AUTOSAR XML (schema 00044)
package /DiagAResourceConsumption/SwAddrMethods
  sw addr method CODE: memory-allocation-keyword-policy=ADDR-METHOD-SHORT-NAME, section-type=CODE
  sw addr method CONST: memory-allocation-keyword-policy=ADDR-METHOD-SHORT-NAME-AND-ALIGNMENT, section-type=CONST
package /ComponentTypes
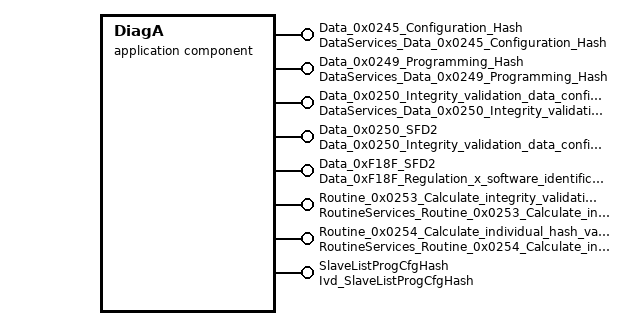
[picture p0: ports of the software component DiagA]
  application sw component type DiagA
    8 x provide port:
      Data_0x0245_Configuration_Hash: provided-interface=DataServices_Data_0x0245_Configuration_Hash
        provided-com-specs:
          operation=DataServices_Data_0x0245_Configuration_Hash/ConditionCheckRead, queue-length=1
          operation=DataServices_Data_0x0245_Configuration_Hash/ReadData, queue-length=1
      Data_0x0249_Programming_Hash: provided-interface=DataServices_Data_0x0249_Programming_Hash
        provided-com-specs:
          operation=DataServices_Data_0x0249_Programming_Hash/ConditionCheckRead, queue-length=1
          operation=DataServices_Data_0x0249_Programming_Hash/ReadData, queue-length=1
      Data_0x0250_Integrity_validation_data_configuration_list: provided-interface=DataServices_Data_0x0250_Integrity_validation_data_configuration_list
        provided-com-specs:
          operation=DataServices_Data_0x0250_Integrity_validation_data_configuration_list/ConditionCheckRead, queue-length=1
          operation=DataServices_Data_0x0250_Integrity_validation_data_configuration_list/ReadData, queue-length=1
          operation=DataServices_Data_0x0250_Integrity_validation_data_configuration_list/ReadDataLength, queue-length=1
          operation=DataServices_Data_0x0250_Integrity_validation_data_configuration_list/WriteData, queue-length=1
      Data_0x0250_SFD2: provided-interface=Data_0x0250_Integrity_validation_data_configuration_list_SFD2
        provided-com-specs:
          operation=Data_0x0250_Integrity_validation_data_configuration_list_SFD2/ConditionCheckRead, queue-length=1
          operation=Data_0x0250_Integrity_validation_data_configuration_list_SFD2/ReadData, queue-length=1
          operation=Data_0x0250_Integrity_validation_data_configuration_list_SFD2/ReadDataLength, queue-length=1
          operation=Data_0x0250_Integrity_validation_data_configuration_list_SFD2/WriteData, queue-length=1
      Data_0xF18F_SFD2: provided-interface=Data_0xF18F_Regulation_x_software_identification_numbers_SFD2
        provided-com-specs:
          operation=Data_0xF18F_Regulation_x_software_identification_numbers_SFD2/ConditionCheckRead, queue-length=1
          operation=Data_0xF18F_Regulation_x_software_identification_numbers_SFD2/ReadData, queue-length=1
          operation=Data_0xF18F_Regulation_x_software_identification_numbers_SFD2/ReadDataLength, queue-length=1
          operation=Data_0xF18F_Regulation_x_software_identification_numbers_SFD2/WriteData, queue-length=1
      Routine_0x0253_Calculate_integrity_validation_data_Start: server-com-spec{operation=RoutineServices_Routine_0x0253_Calculate_integrity_validation_data_Start/Start, queue-length=1}, provided-interface=RoutineServices_Routine_0x0253_Calculate_integrity_validation_data_Start
      Routine_0x0254_Calculate_individual_hash_value_Start: server-com-spec{operation=RoutineServices_Routine_0x0254_Calculate_individual_hash_value_Start/Start, queue-length=1}, provided-interface=RoutineServices_Routine_0x0254_Calculate_individual_hash_value_Start
      SlaveListProgCfgHash: provided-com-specs=[{operation=Data, queue-length=1}, {operation=Hash, queue-length=1}], provided-interface=Ivd_SlaveListProgCfgHash
    behavior DiagA_InternalBehavior
      20 x operation invoked event:
        OIT_Data_0x0245_Configuration_Hash_ConditionCheckRead_Data_0x0245_Configuration_Hash_ConditionCheckRead: start-on-event=Data_0x0245_Configuration_Hash_ConditionCheckRead, operation=Data_0x0245_Configuration_Hash.ConditionCheckRead
        OIT_Data_0x0245_Configuration_Hash_ReadData_Data_0x0245_Configuration_Hash_ReadData: start-on-event=Data_0x0245_Configuration_Hash_ReadData, operation=Data_0x0245_Configuration_Hash.ReadData
        OIT_Data_0x0249_Programming_Hash_ConditionCheckRead_Data_0x0249_Programming_Hash_ConditionCheckRead: start-on-event=Data_0x0249_Programming_Hash_ConditionCheckRead, operation=Data_0x0249_Programming_Hash.ConditionCheckRead
        OIT_Data_0x0249_Programming_Hash_ReadData_Data_0x0249_Programming_Hash_ReadData: start-on-event=Data_0x0249_Programming_Hash_ReadData, operation=Data_0x0249_Programming_Hash.ReadData
        OIT_Data_0x0250_Integrity_validation_data_configuration_list_ConditionCheckRead_Data_0x0250_Integrity_validation_data_coF4607225: start-on-event=Data_0x0250_Integrity_validation_data_configuration_list_ConditionCheckRead, operation=Data_0x0250_Integrity_validation_data_configuration_list.ConditionCheckRead
        OIT_Data_0x0250_Integrity_validation_data_configuration_list_ReadData_Data_0x0250_Integrity_validation_data_configuratio55BBACF9: start-on-event=Data_0x0250_Integrity_validation_data_configuration_list_ReadData, operation=Data_0x0250_Integrity_validation_data_configuration_list.ReadData
        OIT_Data_0x0250_Integrity_validation_data_configuration_list_ReadDataLength_Data_0x0250_Integrity_validation_data_configA7BA6501: start-on-event=Data_0x0250_Integrity_validation_data_configuration_list_ReadDataLength, operation=Data_0x0250_Integrity_validation_data_configuration_list.ReadDataLength
        OIT_Data_0x0250_SFD2_ConditionCheckRead_Data_0x0250_SFD2_ConditionCheckRead: start-on-event=Data_0x0250_Integrity_validation_data_configuration_list_SFD2_ConditionCheckRead, operation=Data_0x0250_SFD2.ConditionCheckRead
        OIT_Data_0x0250_SFD2_ReadData_Data_0x0250_SFD2_ReadData: start-on-event=Data_0x0250_Integrity_validation_data_configuration_list_SFD2_ReadData, operation=Data_0x0250_SFD2.ReadData
        OIT_Data_0x0250_SFD2_ReadDataLength_Data_0x0250_SFD2_ReadDataLength: start-on-event=Data_0x0250_Integrity_validation_data_configuration_list_SFD2_ReadDataLength, operation=Data_0x0250_SFD2.ReadDataLength
        OIT_Data_0x0250_SFD2_WriteData_Data_0x0250_SFD2_WriteData: start-on-event=Data_0x0250_Integrity_validation_data_configuration_list_SFD2_WriteData, operation=Data_0x0250_SFD2.WriteData
        OIT_Data_0x0250_Integrity_validation_data_configuration_list_WriteData_Data_0x0250_Integrity_validation_data_configurati9AFB355F: start-on-event=Data_0x0250_Integrity_validation_data_configuration_list_WriteData, operation=Data_0x0250_Integrity_validation_data_configuration_list.WriteData
        OIT_Data_0xF18F_SFD2_ConditionCheckRead_Data_0xF18F_SFD2_ConditionCheckRead: start-on-event=Data_0xF18F_Regulation_x_software_identification_numbers_SFD2_ConditionCheckRead, operation=Data_0xF18F_SFD2.ConditionCheckRead
        OIT_Data_0xF18F_SFD2_ReadData_Data_0xF18F_SFD2_ReadData: start-on-event=Data_0xF18F_Regulation_x_software_identification_numbers_SFD2_ReadData, operation=Data_0xF18F_SFD2.ReadData
        OIT_Data_0xF18F_SFD2_ReadDataLength_Data_0xF18F_SFD2_ReadDataLength: start-on-event=Data_0xF18F_Regulation_x_software_identification_numbers_SFD2_ReadDataLength, operation=Data_0xF18F_SFD2.ReadDataLength
        OIT_Data_0xF18F_SFD2_WriteData_Data_0xF18F_SFD2_WriteData: start-on-event=Data_0xF18F_Regulation_x_software_identification_numbers_SFD2_WriteData, operation=Data_0xF18F_SFD2.WriteData
        OIT_Routine_0x0253_Calculate_integrity_validation_data_Start_Routine_0x0253_Calculate_integrity_validation_data_Start_Start: start-on-event=Routine_0x0253_Calculate_integrity_validation_data_Start, operation=Routine_0x0253_Calculate_integrity_validation_data_Start.Start
        OIT_Routine_0x0254_Calculate_individual_hash_value_Start_Routine_0x0254_Calculate_individual_hash_value_Start_Start: start-on-event=Routine_0x0254_Calculate_individual_hash_value_Start, operation=Routine_0x0254_Calculate_individual_hash_value_Start.Start
        OIT_SlaveListProgCfgHash_Data_SlaveListProgCfgHash_Data: start-on-event=SlaveListProgCfgHash_Data, operation=SlaveListProgCfgHash.Data
        OIT_SlaveListProgCfgHash_Hash_SlaveListProgCfgHash_Hash: start-on-event=SlaveListProgCfgHash_Hash, operation=SlaveListProgCfgHash.Hash
      20 x runnable:
        Data_0x0245_Configuration_Hash_ConditionCheckRead: symbol=Data0x0245_ConditionCheckRead
        Data_0x0245_Configuration_Hash_ReadData: symbol=Data0x0245_ReadData
        Data_0x0249_Programming_Hash_ConditionCheckRead: symbol=Data0x0249_ConditionCheckRead
        Data_0x0249_Programming_Hash_ReadData: symbol=Data0x0249_ReadData
        Data_0x0250_Integrity_validation_data_configuration_list_ConditionCheckRead: symbol=Data0x0250_ConditionCheckRead
        Data_0x0250_Integrity_validation_data_configuration_list_ReadData: symbol=Data0x0250_ReadData
        Data_0x0250_Integrity_validation_data_configuration_list_ReadDataLength: symbol=Data0x0250_ReadDataLength
        Data_0x0250_Integrity_validation_data_configuration_list_SFD2_ConditionCheckRead: symbol=Data0x0250Sfd2_ConditionCheckRead
        Data_0x0250_Integrity_validation_data_configuration_list_SFD2_ReadData: symbol=Data0x0250Sfd2_ReadData
        Data_0x0250_Integrity_validation_data_configuration_list_SFD2_ReadDataLength: symbol=Data0x0250Sfd2_ReadDataLength
        Data_0x0250_Integrity_validation_data_configuration_list_SFD2_WriteData: symbol=Data0x0250Sfd2_WriteData
        Data_0x0250_Integrity_validation_data_configuration_list_WriteData: symbol=Data0x0250_WriteData
        Data_0xF18F_Regulation_x_software_identification_numbers_SFD2_ConditionCheckRead: symbol=Data0xF18FSfd2_ConditionCheckRead
        Data_0xF18F_Regulation_x_software_identification_numbers_SFD2_ReadData: symbol=Data0xF18FSfd2_ReadData
        Data_0xF18F_Regulation_x_software_identification_numbers_SFD2_ReadDataLength: symbol=Data0xF18FSfd2_ReadDataLength
        Data_0xF18F_Regulation_x_software_identification_numbers_SFD2_WriteData: symbol=Data0xF18FSfd2_WriteData
        Routine_0x0253_Calculate_integrity_validation_data_Start: symbol=Routine0x0253_Start
        Routine_0x0254_Calculate_individual_hash_value_Start: symbol=Routine0x0254_Start
        SlaveListProgCfgHash_Data
        SlaveListProgCfgHash_Hash
  swc implementation DiagA_Implementation: vendor-id=75, behavior=DiagA_InternalBehavior
    code-descriptors:
      code Default: artifact-descriptors=autosar-engineering-object={short-label=Default, category=SWSRC}
    resource consumption ResourceConsumption
      memory section CODE: sw-addrmethod=CODE
      memory section CONST_UNSPECIFIED: alignment=UNSPECIFIED, sw-addrmethod=CONST
package /DataTypes
  impl type Ivd_32ByteHash: category=ARRAY, sw-calibration-access=READ-ONLY, type-emitter=RTE
    element Element: array-size=32, array-size-semantics=FIXED-SIZE, implementation-data-type=uint8
  impl type Ivd_Data128Byte: category=ARRAY, sw-calibration-access=READ-ONLY, type-emitter=RTE
    element Element: array-size=128, array-size-semantics=FIXED-SIZE, implementation-data-type=uint8
package /Ivd/DataTypes
  5 x impl type:
    Dcm_Data2ByteType: category=ARRAY, sw-calibration-access=READ-ONLY
      element Dcm_Data2ByteTypeElement: array-size=2, array-size-semantics=FIXED-SIZE, implementation-data-type=uint8
    Dcm_Data32ByteType: category=ARRAY, sw-calibration-access=READ-ONLY
      element Dcm_Data32ByteTypeElement: array-size=32, array-size-semantics=FIXED-SIZE, implementation-data-type=uint8
    Dcm_Data4096ByteType: category=ARRAY, sw-calibration-access=READ-ONLY
      element Dcm_Data4096ByteTypeElement: array-size=4096, array-size-semantics=FIXED-SIZE, implementation-data-type=uint8
    Dcm_NegativeResponseCodeType:
      compu {0=DCM_E_POSITIVERESPONSE, 16=DCM_E_GENERALREJECT, 17=DCM_E_SERVICENOTSUPPORTED, 18=DCM_E_SUBFUNCTIONNOTSUPPORTED, 19=DCM_E_INCORRECTMESSAGELENGTHORINVALIDFORMAT, 20=DCM_E_RESPONSETOOLONG, 33=DCM_E_BUSYREPEATREQUEST, 34=DCM_E_CONDITIONSNOTCORRECT, 36=DCM_E_REQUESTSEQUENCEERROR, 37=DCM_E_NORESPONSEFROMSUBNETCOMPONENT, 38=DCM_E_FAILUREPREVENTSEXECUTIONOFREQUESTEDACTION, 49=DCM_E_REQUESTOUTOFRANGE, 51=DCM_E_SECURITYACCESSDENIED, 53=DCM_E_INVALIDKEY, 54=DCM_E_EXCEEDNUMBEROFATTEMPTS, 55=DCM_E_REQUIREDTIMEDELAYNOTEXPIRED, 112=DCM_E_UPLOADDOWNLOADNOTACCEPTED, 113=DCM_E_TRANSFERDATASUSPENDED, 114=DCM_E_GENERALPROGRAMMINGFAILURE, 115=DCM_E_WRONGBLOCKSEQUENCECOUNTER, 120=DCM_E_REQUESTCORRECTLYRECEIVEDRESPONSEPENDING, 126=DCM_E_SUBFUNCTIONNOTSUPPORTEDINACTIVESESSION, 127=DCM_E_SERVICENOTSUPPORTEDINACTIVESESSION, 129=DCM_E_RPMTOOHIGH, 130=DCM_E_RPMTOOLOW, 131=DCM_E_ENGINEISRUNNING, 132=DCM_E_ENGINEISNOTRUNNING, 133=DCM_E_ENGINERUNTIMETOOLOW, 134=DCM_E_TEMPERATURETOOHIGH, 135=DCM_E_TEMPERATURETOOLOW, 136=DCM_E_VEHICLESPEEDTOOHIGH, 137=DCM_E_VEHICLESPEEDTOOLOW, 138=DCM_E_THROTTLE_PEDALTOOHIGH, 139=DCM_E_THROTTLE_PEDALTOOLOW, 140=DCM_E_TRANSMISSIONRANGENOTINNEUTRAL, 141=DCM_E_TRANSMISSIONRANGENOTINGEAR, 143=DCM_E_BRAKESWITCH_NOTCLOSED, 144=DCM_E_SHIFTERLEVERNOTINPARK, 145=DCM_E_TORQUECONVERTERCLUTCHLOCKED, 146=DCM_E_VOLTAGETOOHIGH, 147=DCM_E_VOLTAGETOOLOW, 240..249=DCM_E_VMSCNC_0..DCM_E_VMSCNC_9, 250=DCM_E_VMSCNC_A, 251=DCM_E_VMSCNC_B, 252=DCM_E_VMSCNC_C, 253=DCM_E_VMSCNC_D, 254=DCM_E_VMSCNC_E}
      range raw 0..254
      implementation-data-type=uint8
    Dcm_OpStatusType: compu {0=DCM_INITIAL, 1=DCM_PENDING, 2=DCM_CANCEL, 3=DCM_FORCE_RCRRP_OK, 64=DCM_FORCE_RCRRP_NOT_OK}, range raw 0..64, implementation-data-type=uint8
package /Ivd/Interfaces
  5 x client server interface, all with is-service=true, service-kind=DIAGNOSTIC-COMMUNICATION-MANAGER:
    DataServices_Data_0x0245_Configuration_Hash
      operation ConditionCheckRead: possible-error=[DataServices_Data_0x0245_Configuration_Hash/DCM_E_PENDING, DataServices_Data_0x0245_Configuration_Hash/E_NOT_OK]
        arg OpStatus: type=Dcm_OpStatusType, direction=IN, server-argument-impl-policy=USE-ARGUMENT-TYPE
        arg ErrorCode: type=Dcm_NegativeResponseCodeType, direction=OUT, server-argument-impl-policy=USE-ARGUMENT-TYPE
      operation ReadData: possible-error=[DataServices_Data_0x0245_Configuration_Hash/DCM_E_PENDING, DataServices_Data_0x0245_Configuration_Hash/E_NOT_OK]
        arg OpStatus: type=Dcm_OpStatusType, direction=IN, server-argument-impl-policy=USE-ARGUMENT-TYPE
        arg Data: type=Dcm_Data32ByteType, direction=OUT, server-argument-impl-policy=USE-ARRAY-BASE-TYPE
      error DCM_E_PENDING: error-code=10
      error E_NOT_OK: error-code=1
    DataServices_Data_0x0249_Programming_Hash
      operation ConditionCheckRead: possible-error=[DataServices_Data_0x0249_Programming_Hash/DCM_E_PENDING, DataServices_Data_0x0249_Programming_Hash/E_NOT_OK]
        arg OpStatus: type=Dcm_OpStatusType, direction=IN, server-argument-impl-policy=USE-ARGUMENT-TYPE
        arg ErrorCode: type=Dcm_NegativeResponseCodeType, direction=OUT, server-argument-impl-policy=USE-ARGUMENT-TYPE
      operation ReadData: possible-error=[DataServices_Data_0x0249_Programming_Hash/DCM_E_PENDING, DataServices_Data_0x0249_Programming_Hash/E_NOT_OK]
        arg OpStatus: type=Dcm_OpStatusType, direction=IN, server-argument-impl-policy=USE-ARGUMENT-TYPE
        arg Data: type=Dcm_Data32ByteType, direction=OUT, server-argument-impl-policy=USE-ARRAY-BASE-TYPE
      error DCM_E_PENDING: error-code=10
      error E_NOT_OK: error-code=1
    DataServices_Data_0x0250_Integrity_validation_data_configuration_list
      4 x operation, all with possible-error=[DataServices_Data_0x0250_Integrity_validation_data_configuration_list/DCM_E_PENDING, DataServices_Data_0x0250_Integrity_validation_data_configuration_list/E_NOT_OK]:
        ConditionCheckRead
          arg OpStatus: type=Dcm_OpStatusType, direction=IN, server-argument-impl-policy=USE-ARGUMENT-TYPE
          arg ErrorCode: type=Dcm_NegativeResponseCodeType, direction=OUT, server-argument-impl-policy=USE-ARGUMENT-TYPE
        ReadData
          arg OpStatus: type=Dcm_OpStatusType, direction=IN, server-argument-impl-policy=USE-ARGUMENT-TYPE
          arg Data: type=Dcm_Data4096ByteType, direction=OUT, server-argument-impl-policy=USE-ARRAY-BASE-TYPE
        ReadDataLength
          arg OpStatus: type=Dcm_OpStatusType, direction=IN, server-argument-impl-policy=USE-ARGUMENT-TYPE
          arg DataLength: type=uint16, direction=OUT, server-argument-impl-policy=USE-ARGUMENT-TYPE
        WriteData
          4 x arg:
            Data: type=Dcm_Data4096ByteType, direction=IN, server-argument-impl-policy=USE-ARRAY-BASE-TYPE
            DataLength: type=uint16, direction=IN, server-argument-impl-policy=USE-ARGUMENT-TYPE
            OpStatus: type=Dcm_OpStatusType, direction=IN, server-argument-impl-policy=USE-ARGUMENT-TYPE
            ErrorCode: type=Dcm_NegativeResponseCodeType, direction=OUT, server-argument-impl-policy=USE-ARGUMENT-TYPE
      error DCM_E_PENDING: error-code=10
      error E_NOT_OK: error-code=1
    RoutineServices_Routine_0x0253_Calculate_integrity_validation_data_Start
      operation Start: possible-error=[RoutineServices_Routine_0x0253_Calculate_integrity_validation_data_Start/DCM_E_FORCE_RCRRP, RoutineServices_Routine_0x0253_Calculate_integrity_validation_data_Start/DCM_E_PENDING, RoutineServices_Routine_0x0253_Calculate_integrity_validation_data_Start/E_NOT_OK]
        6 x arg:
          Type_of_calculation: type=uint8, direction=IN, server-argument-impl-policy=USE-ARGUMENT-TYPE
          Type_of_hash_value: type=uint8, direction=IN, server-argument-impl-policy=USE-ARGUMENT-TYPE
          OpStatus: type=Dcm_OpStatusType, direction=IN, server-argument-impl-policy=USE-ARGUMENT-TYPE
          ResData: type=Dcm_Data4096ByteType, direction=OUT, server-argument-impl-policy=USE-ARRAY-BASE-TYPE
          DataLength: type=uint16, direction=OUT, server-argument-impl-policy=USE-ARGUMENT-TYPE
          ErrorCode: type=Dcm_NegativeResponseCodeType, direction=OUT, server-argument-impl-policy=USE-ARGUMENT-TYPE
      error DCM_E_FORCE_RCRRP: error-code=12
      error DCM_E_PENDING: error-code=10
      error E_NOT_OK: error-code=1
    RoutineServices_Routine_0x0254_Calculate_individual_hash_value_Start
      operation Start: possible-error=[RoutineServices_Routine_0x0254_Calculate_individual_hash_value_Start/DCM_E_FORCE_RCRRP, RoutineServices_Routine_0x0254_Calculate_individual_hash_value_Start/DCM_E_PENDING, RoutineServices_Routine_0x0254_Calculate_individual_hash_value_Start/E_NOT_OK]
        7 x arg:
          Type_of_hash_value: type=uint8, direction=IN, server-argument-impl-policy=USE-ARGUMENT-TYPE
          Type_of_hash: type=uint8, direction=IN, server-argument-impl-policy=USE-ARGUMENT-TYPE
          Individual_hash_value_id: type=Dcm_Data2ByteType, direction=IN, server-argument-impl-policy=USE-ARRAY-BASE-TYPE
          OpStatus: type=Dcm_OpStatusType, direction=IN, server-argument-impl-policy=USE-ARGUMENT-TYPE
          ResData: type=Dcm_Data4096ByteType, direction=OUT, server-argument-impl-policy=USE-ARRAY-BASE-TYPE
          DataLength: type=uint16, direction=OUT, server-argument-impl-policy=USE-ARGUMENT-TYPE
          ErrorCode: type=Dcm_NegativeResponseCodeType, direction=OUT, server-argument-impl-policy=USE-ARGUMENT-TYPE
      error DCM_E_FORCE_RCRRP: error-code=12
      error DCM_E_PENDING: error-code=10
      error E_NOT_OK: error-code=1
package /PortInterfaces
  client server interface Data_0x0250_Integrity_validation_data_configuration_list_SFD2
    4 x operation, all with possible-error=[Data_0x0250_Integrity_validation_data_configuration_list_SFD2/DCM_E_PENDING, Data_0x0250_Integrity_validation_data_configuration_list_SFD2/E_NOT_OK]:
      ConditionCheckRead
        arg OpStatus: type=Dcm_OpStatusType, direction=IN, server-argument-impl-policy=USE-ARGUMENT-TYPE
        arg ErrorCode: type=Dcm_NegativeResponseCodeType, direction=OUT, server-argument-impl-policy=USE-ARGUMENT-TYPE
      ReadData
        arg OpStatus: type=Dcm_OpStatusType, direction=IN, server-argument-impl-policy=USE-ARGUMENT-TYPE
        arg Data: type=Dcm_Data4096ByteType, direction=OUT, server-argument-impl-policy=USE-ARRAY-BASE-TYPE
      ReadDataLength
        arg OpStatus: type=Dcm_OpStatusType, direction=IN, server-argument-impl-policy=USE-ARGUMENT-TYPE
        arg DidLength: type=uint16, direction=OUT, server-argument-impl-policy=USE-ARGUMENT-TYPE
      WriteData
        4 x arg:
          Data: type=Dcm_Data4096ByteType, direction=IN, server-argument-impl-policy=USE-ARRAY-BASE-TYPE
          DataLength: type=uint16, direction=IN, server-argument-impl-policy=USE-ARGUMENT-TYPE
          OpStatus: type=Dcm_OpStatusType, direction=IN, server-argument-impl-policy=USE-ARGUMENT-TYPE
          ErrorCode: type=Dcm_NegativeResponseCodeType, direction=OUT, server-argument-impl-policy=USE-ARGUMENT-TYPE
    error DCM_E_PENDING: error-code=10
    error E_NOT_OK: error-code=1
  client server interface Data_0xF18F_Regulation_x_software_identification_numbers_SFD2
    4 x operation, all with possible-error=[Data_0xF18F_Regulation_x_software_identification_numbers_SFD2/DCM_E_PENDING, Data_0xF18F_Regulation_x_software_identification_numbers_SFD2/E_NOT_OK]:
      ConditionCheckRead
        arg OpStatus: type=Dcm_OpStatusType, direction=IN, server-argument-impl-policy=USE-ARGUMENT-TYPE
        arg ErrorCode: type=Dcm_NegativeResponseCodeType, direction=OUT, server-argument-impl-policy=USE-ARGUMENT-TYPE
      ReadData
        arg OpStatus: type=Dcm_OpStatusType, direction=IN, server-argument-impl-policy=USE-ARGUMENT-TYPE
        arg Data: type=Dcm_Data4096ByteType, direction=OUT, server-argument-impl-policy=USE-ARRAY-BASE-TYPE
      ReadDataLength
        arg OpStatus: type=Dcm_OpStatusType, direction=IN, server-argument-impl-policy=USE-ARGUMENT-TYPE
        arg DidLength: type=uint16, direction=OUT, server-argument-impl-policy=USE-ARGUMENT-TYPE
      WriteData
        4 x arg:
          Data: type=Dcm_Data4096ByteType, direction=IN, server-argument-impl-policy=USE-ARRAY-BASE-TYPE
          DataLength: type=uint16, direction=IN, server-argument-impl-policy=USE-ARGUMENT-TYPE
          OpStatus: type=Dcm_OpStatusType, direction=IN, server-argument-impl-policy=USE-ARGUMENT-TYPE
          ErrorCode: type=Dcm_NegativeResponseCodeType, direction=OUT, server-argument-impl-policy=USE-ARGUMENT-TYPE
    error DCM_E_PENDING: error-code=10
    error E_NOT_OK: error-code=1
  client server interface Ivd_SlaveListProgCfgHash
    operation Data: possible-error=[Ivd_SlaveListProgCfgHash/E_NOT_OK, E_PENDING, E_SMALL_BUFFER]
      arg DataBuffer: type=Ivd_Data128Byte, direction=IN, server-argument-impl-policy=USE-ARRAY-BASE-TYPE
      arg DataLength: type=uint8, direction=IN, server-argument-impl-policy=USE-ARGUMENT-TYPE
      arg Cmd: type=uint8, direction=IN, server-argument-impl-policy=USE-ARGUMENT-TYPE
    operation Hash: possible-error=[E_DATA_INVALID, Ivd_SlaveListProgCfgHash/E_NOT_OK]
      arg PtrHashValue: type=Ivd_32ByteHash, direction=OUT, server-argument-impl-policy=USE-ARRAY-BASE-TYPE
    4 x error:
      E_DATA_INVALID: error-code=2
      E_NOT_OK: error-code=1
      E_PENDING: error-code=10
      E_SMALL_BUFFER: error-code=3
